//********************************************************************
// file: lin_pp515.ldf
// description: LIN decription file (LDF) for the PP515 Arrival Button
// author: James Fletcher
// date: 2019-03-26
// (c) The Invent Hive

//********************************************************************
// History
// 2019-03-26 0.01 Initial Release
// 2019-08-19 0.02 Added RGB triple for anim tint to masterCommandsFrame. Used to colour playing anim.
// Reduced byte count of buttonStatusFrame to better fit data and improve bus load.
// 2019-09-20	1.00 Ammended to new scheme supporting addressing on multiple buttons
// 2019-12-12 1.1 Converted to ARRIVAL VAN Dashboard LIN with Juoku stalk added - Chris Mather
// 2019-12-13	2.0 Imported Hella Rain Light Sensor LDF to complete dash LIN - Chris Mather
// 2020-01-07	3.0 Added LH_Stalk response error
// header

LIN_description_file;
LIN_protocol_version = "2.1";
LIN_language_version = "2.1";
LIN_speed = 19.2 kbps;

Nodes {
  Master: master, 10 ms, 0.1 ms ;
  Slaves: button1, button2, button3, button4, button5, button6, button7, button8, button9, button10, button11, button12, button13, button14, LH_Stalk, RLS_LIN ;
}

Signals {
  MASTER_Status: 8, 0, master, button1, button2 ;
  MASTER_ConfigReset: 1, 0, master, button1, button2 ;
  MASTER_ConfigEnable: 1, 0, master, button1, button2 ;
  MASTER_ConfigSetPIDOffset: 8, 0, master, button1, button2 ;
  BUTTYPE0_DefaultAnim: 8, 0, master ;
  BUTTYPE0_DefaultAnimTintR: 8, 96, master ;
  BUTTYPE0_DefaultAnimTintG: 8, 64, master ;
  BUTTYPE0_DefaultAnimTintB: 8, 64, master ;
  BUTTYPE0_TouchAnim: 8, 1, master ;
  BUTTYPE0_TouchAnimTintR: 8, 255, master ;
  BUTTYPE0_TouchAnimTintG: 8, 0, master ;
  BUTTYPE0_TouchAnimTintB: 8, 0, master ;
  BUTTYPE0_LockedAnim: 8, 0, master ;
  BUTTYPE0_LockedAnimTintR: 8, 255, master ;
  BUTTYPE0_LockedAnimTintG: 8, 0, master ;
  BUTTYPE0_LockedAnimTintB: 8, 0, master ;
  BUTTYPE1_DefaultAnim: 8, 0, master ;
  BUTTYPE1_DefaultAnimTintR: 8, 96, master ;
  BUTTYPE1_DefaultAnimTintG: 8, 64, master ;
  BUTTYPE1_DefaultAnimTintB: 8, 64, master ;
  BUTTYPE1_TouchAnim: 8, 2, master ;
  BUTTYPE1_TouchAnimTintR: 8, 0, master ;
  BUTTYPE1_TouchAnimTintG: 8, 0, master ;
  BUTTYPE1_TouchAnimTintB: 8, 255, master ;
  BUTTYPE1_LockedAnim: 8, 0, master ;
  BUTTYPE1_LockedAnimTintR: 8, 255, master ;
  BUTTYPE1_LockedAnimTintG: 8, 0, master ;
  BUTTYPE1_LockedAnimTintB: 8, 0, master ;
  BUTTON1_Type: 4, 0, master ;
  BUTTON1_LockedOut: 1, 0, master ;
  BUTTON2_Type: 4, 0, master ;
  BUTTON2_LockedOut: 1, 0, master ;
  BUTTON3_Type: 4, 0, master ;
  BUTTON3_LockedOut: 1, 0, master ;
  BUTTON4_Type: 4, 0, master ;
  BUTTON4_LockedOut: 1, 0, master ;
  BUTTON5_Type: 4, 0, master ;
  BUTTON5_LockedOut: 1, 0, master ;
  BUTTON6_Type: 4, 0, master ;
  BUTTON6_LockedOut: 1, 0, master ;
  BUTTON7_Type: 4, 0, master ;
  BUTTON7_LockedOut: 1, 0, master ;
  BUTTON8_Type: 4, 0, master ;
  BUTTON8_LockedOut: 1, 0, master ;
  BUTTON9_Type: 4, 0, master ;
  BUTTON9_LockedOut: 1, 0, master ;
  BUTTON10_Type: 4, 0, master ;
  BUTTON10_LockedOut: 1, 0, master ;
  BUTTON11_Type: 4, 0, master ;
  BUTTON11_LockedOut: 1, 0, master ;
  BUTTON12_Type: 4, 0, master ;
  BUTTON12_LockedOut: 1, 0, master ;
  BUTTON13_Type: 4, 0, master ;
  BUTTON13_LockedOut: 1, 0, master ;
  BUTTON14_Type: 4, 0, master ;
  BUTTON14_LockedOut: 1, 0, master ;
  BUTTON1_Touched: 1, 0, button1 ;
  BUTTON1_TouchTimer: 16, 0, button1 ;
  BUTTON1_Error: 1, 0, button1 ;
  BUTTON2_Touched: 1, 0, button2 ;
  BUTTON2_TouchTimer: 16, 0, button2 ;
  BUTTON2_Error: 1, 0, button2 ;
  BUTTON3_Touched: 1, 0, button3 ;
  BUTTON3_TouchTimer: 16, 0, button3 ;
  BUTTON3_Error: 1, 0, button3 ;
  BUTTON4_Touched: 1, 0, button4 ;
  BUTTON4_TouchTimer: 16, 0, button4 ;
  BUTTON4_Error: 1, 0, button4 ;
  BUTTON5_Touched: 1, 0, button5 ;
  BUTTON5_TouchTimer: 16, 0, button5 ;
  BUTTON5_Error: 1, 0, button5 ;
  BUTTON6_Touched: 1, 0, button6 ;
  BUTTON6_TouchTimer: 16, 0, button6 ;
  BUTTON6_Error: 1, 0, button6 ;
  BUTTON7_Touched: 1, 0, button7 ;
  BUTTON7_TouchTimer: 16, 0, button7 ;
  BUTTON7_Error: 1, 0, button7 ;
  BUTTON8_Touched: 1, 0, button8 ;
  BUTTON8_TouchTimer: 16, 0, button8 ;
  BUTTON8_Error: 1, 0, button8 ;
  BUTTON9_Touched: 1, 0, button9 ;
  BUTTON9_TouchTimer: 16, 0, button9 ;
  BUTTON9_Error: 1, 0, button9 ;
  BUTTON10_Touched: 1, 0, button10 ;
  BUTTON10_TouchTimer: 16, 0, button10 ;
  BUTTON10_Error: 1, 0, button10 ;
  BUTTON11_Touched: 1, 0, button11 ;
  BUTTON11_TouchTimer: 16, 0, button11 ;
  BUTTON11_Error: 1, 0, button11 ;
  BUTTON12_Touched: 1, 0, button12 ;
  BUTTON12_TouchTimer: 16, 0, button12 ;
  BUTTON12_Error: 1, 0, button12 ;
  BUTTON13_Touched: 1, 0, button13 ;
  BUTTON13_TouchTimer: 16, 0, button13 ;
  BUTTON13_Error: 1, 0, button13 ;
  BUTTON14_Touched: 1, 0, button14 ;
  BUTTON14_TouchTimer: 16, 0, button14 ;
  BUTTON14_Error: 1, 0, button14 ;
  Hi_Beam_Half_Pull: 1, 0, LH_Stalk, master ;
  Hi_Beam_Full_Pull: 1, 0, LH_Stalk, master ;
  Indicator_Half_Up: 1, 0, LH_Stalk, master ;
  Indicator_Full_Up: 1, 0, LH_Stalk, master ;
  Indicator_Half_Down: 1, 0, LH_Stalk, master ;
  Indicator_Full_Down: 1, 0, LH_Stalk, master ;
  Wiper_Half_Push: 1, 0, LH_Stalk, master ;
  Wiper_Full_Push: 1, 0, LH_Stalk, master ;
  Over_Voltage: 1, 0, LH_Stalk, master ;
  Over_Temperature: 1, 0, LH_Stalk, master ;
  LHSTALK_ERROR: 1, 0, LH_Stalk, master ;
  WIPER_SPEED: 4, 15, RLS_LIN, master ;
  STATUS_RAIN_SENS: 4, 15, RLS_LIN, master ;
  LIGHT_SWITCH_REASON: 8, 255, RLS_LIN, master ;
  RAIN_INTENSITY: 4, 15, RLS_LIN, master ;
  LIGHT_SWITCH_REQUEST: 2, 3, RLS_LIN, master ;
  STATUS_LIGHT_SENS: 2, 3, RLS_LIN, master ;
  AMBIENT_BRIGHTNESS: 8, 255, RLS_LIN, master ;
  FRONT_BRIGHTNESS: 8, 255, RLS_LIN, master ;
  ERR_STATE_CAL_RAIN_SENS: 2, 3, RLS_LIN, master ;
  ERR_STATE_RAIN_SENS: 2, 3, RLS_LIN, master ;
  ERR_STATE_CODING: 2, 3, RLS_LIN, master ;
  ERR_STATE_LIGHT_SENS: 2, 3, RLS_LIN, master ;
  ERR_STATE_OVER_TEMP: 2, 3, RLS_LIN, master ;
  ERR_STATE_OVER_VOLT: 2, 3, RLS_LIN, master ;
  SIGNAL_ERROR: 2, 3, RLS_LIN, master ;
  COMM_ERROR: 1, 0, RLS_LIN, master ;
  SCREEN_TYPE_RLS: 4, 15, RLS_LIN, master ;
  VEH_TYPE_RLS: 3, 7, RLS_LIN, master ;
  ACTIVATION_WIPE_RLS: 1, 1, RLS_LIN, master ;
  WIPER_TYPE_RLS: 2, 3, RLS_LIN, master ;
  WIPERS_OVER_SENSOR_RLS: 2, 3, RLS_LIN, master ;
  FEEDBACK_WIPE_RLS: 1, 1, RLS_LIN, master ;
  INITIALIZATION_WIPE_RLS: 1, 1, RLS_LIN, master ;
  SPEED_LIGHT_RLS: 2, 3, RLS_LIN, master ;
  LIGHT_SENSITIVITY_RLS: 4, 15, RLS_LIN, master ;
  ADDITIONAL_WIPE_TUNNEL_RLS: 1, 1, RLS_LIN, master ;
  SALT_DETECTION_RLS: 1, 1, RLS_LIN, master ;
  ICE_DETECTION_RLS: 1, 1, RLS_LIN, master ;
  RAIN_LIGHT_RLS: 1, 1, RLS_LIN, master ;
  AFTER_TUNNEL_DELAY_RLS: 8, 255, RLS_LIN, master ;
  PROD_DAY_RLS: 5, 31, RLS_LIN, master ;
  PROD_MONTH_RLS: 4, 15, RLS_LIN, master ;
  PROD_YEAR_RLS: 5, 31, RLS_LIN, master ;
  SW_MAJOR_VERSION_RLS: 4, 15, RLS_LIN, master ;
  SW_MINOR_VERSION_RLS: 4, 15, RLS_LIN, master ;
  HW_MAJOR_VERSION_RLS: 4, 15, RLS_LIN, master ;
  HW_MINOR_VERSION_RLS: 4, 15, RLS_LIN, master ;
  STATE_IGNITION: 4, 15, master, RLS_LIN ;
  WIPER_CONTROL: 8, 255, master, RLS_LIN ;
  WIPER_POSITION: 4, 15, master, RLS_LIN ;
  TEMP_EX: 16, 65535, master, RLS_LIN ;
  VEH_SPEED: 16, 65535, master, RLS_LIN ;
  RAIN_SENSITIVITY: 4, 15, master, RLS_LIN ;
  SCREEN_TYPE: 4, 15, master, RLS_LIN ;
  VEH_TYPE: 3, 7, master, RLS_LIN ;
  ACTIVATION_WIPE: 1, 1, master, RLS_LIN ;
  WIPER_TYPE: 2, 3, master, RLS_LIN ;
  WIPERS_OVER_SENSOR: 2, 3, master, RLS_LIN ;
  FEEDBACK_WIPE: 1, 1, master, RLS_LIN ;
  INITIALIZATION_WIPE: 1, 1, master, RLS_LIN ;
  SPEED_LIGHT: 2, 3, master, RLS_LIN ;
  LIGHT_SENSITIVITY: 4, 15, master, RLS_LIN ;
  ADDITIONAL_WIPE_TUNNEL: 1, 1, master, RLS_LIN ;
  SALT_DETECTION: 1, 1, master, RLS_LIN ;
  ICE_DETECTION: 1, 1, master, RLS_LIN ;
  RAIN_LIGHT: 1, 1, master, RLS_LIN ;
  AFTER_TUNNEL_DELAY: 8, 255, master, RLS_LIN ;
}

Frames {
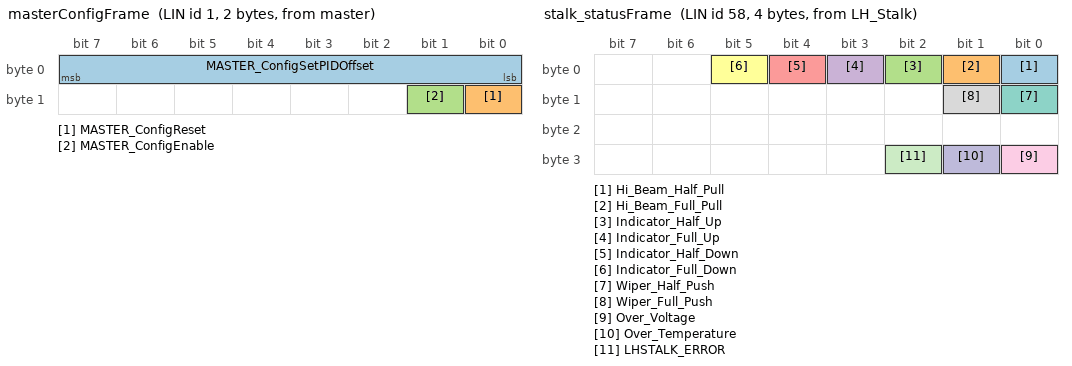
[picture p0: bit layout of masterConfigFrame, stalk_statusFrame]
  masterConfigFrame: 1, master, 2 {
    MASTER_ConfigSetPIDOffset, 0 ;
    MASTER_ConfigReset, 8 ;
    MASTER_ConfigEnable, 9 ;
  }
  masterStatusFrame: 3, master, 1 {
    MASTER_Status, 0 ;
  }
  stalk_statusFrame: 58, LH_Stalk, 4 {
    Hi_Beam_Half_Pull, 0 ;
    Hi_Beam_Full_Pull, 1 ;
    Indicator_Half_Up, 2 ;
    Indicator_Full_Up, 3 ;
    Indicator_Half_Down, 4 ;
    Indicator_Full_Down, 5 ;
    Wiper_Half_Push, 8 ;
    Wiper_Full_Push, 9 ;
    Over_Voltage, 24 ;
    Over_Temperature, 25 ;
    LHSTALK_ERROR, 26 ;
  }
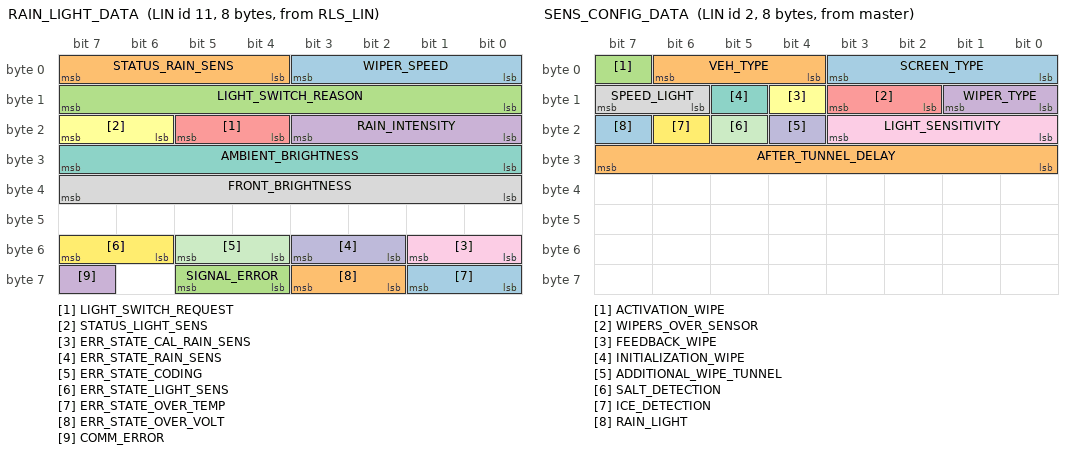
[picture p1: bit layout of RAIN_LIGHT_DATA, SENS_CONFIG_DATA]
  RAIN_LIGHT_DATA: 11, RLS_LIN, 8 {
    WIPER_SPEED, 0 ;
    STATUS_RAIN_SENS, 4 ;
    LIGHT_SWITCH_REASON, 8 ;
    RAIN_INTENSITY, 16 ;
    LIGHT_SWITCH_REQUEST, 20 ;
    STATUS_LIGHT_SENS, 22 ;
    AMBIENT_BRIGHTNESS, 24 ;
    FRONT_BRIGHTNESS, 32 ;
    ERR_STATE_CAL_RAIN_SENS, 48 ;
    ERR_STATE_RAIN_SENS, 50 ;
    ERR_STATE_CODING, 52 ;
    ERR_STATE_LIGHT_SENS, 54 ;
    ERR_STATE_OVER_TEMP, 56 ;
    ERR_STATE_OVER_VOLT, 58 ;
    SIGNAL_ERROR, 60 ;
    COMM_ERROR, 63 ;
  }
  SENS_CONFIG_DATA: 2, master, 8 {
    SCREEN_TYPE, 0 ;
    VEH_TYPE, 4 ;
    ACTIVATION_WIPE, 7 ;
    WIPER_TYPE, 8 ;
    WIPERS_OVER_SENSOR, 10 ;
    FEEDBACK_WIPE, 12 ;
    INITIALIZATION_WIPE, 13 ;
    SPEED_LIGHT, 14 ;
    LIGHT_SENSITIVITY, 16 ;
    ADDITIONAL_WIPE_TUNNEL, 20 ;
    SALT_DETECTION, 21 ;
    ICE_DETECTION, 22 ;
    RAIN_LIGHT, 23 ;
    AFTER_TUNNEL_DELAY, 24 ;
  }
  SENS_STORED_DATA: 23, RLS_LIN, 8 {
    SCREEN_TYPE_RLS, 0 ;
    VEH_TYPE_RLS, 4 ;
    ACTIVATION_WIPE_RLS, 7 ;
    WIPER_TYPE_RLS, 8 ;
    WIPERS_OVER_SENSOR_RLS, 10 ;
    FEEDBACK_WIPE_RLS, 12 ;
    INITIALIZATION_WIPE_RLS, 13 ;
    SPEED_LIGHT_RLS, 14 ;
    LIGHT_SENSITIVITY_RLS, 16 ;
    ADDITIONAL_WIPE_TUNNEL_RLS, 20 ;
    SALT_DETECTION_RLS, 21 ;
    ICE_DETECTION_RLS, 22 ;
    RAIN_LIGHT_RLS, 23 ;
    AFTER_TUNNEL_DELAY_RLS, 24 ;
    PROD_DAY_RLS, 34 ;
    PROD_MONTH_RLS, 39 ;
    PROD_YEAR_RLS, 43 ;
    SW_MAJOR_VERSION_RLS, 48 ;
    SW_MINOR_VERSION_RLS, 52 ;
    HW_MAJOR_VERSION_RLS, 56 ;
    HW_MINOR_VERSION_RLS, 60 ;
  }
}

Node_attributes {
  button1{
    LIN_protocol = "2.1" ;
    configured_NAD = 0x1 ;
    initial_NAD = 0xA ;
    product_id = 0x1234, 0x5678, 1 ;
    response_error = BUTTON1_Error ;
    P2_min = 100 ms ;
    ST_min = 20 ms ;
    N_As_timeout = 1000 ms ;
    N_Cr_timeout = 1000 ms ;
    configurable_frames {
      masterConfigFrame ;
      masterStatusFrame ;
    }
  }
  button2{
    LIN_protocol = "2.1" ;
    configured_NAD = 0x1 ;
    initial_NAD = 0xB ;
    product_id = 0x1234, 0x5678, 2 ;
    response_error = BUTTON2_Error ;
    P2_min = 100 ms ;
    ST_min = 20 ms ;
    N_As_timeout = 1000 ms ;
    N_Cr_timeout = 1000 ms ;
    configurable_frames {
      masterConfigFrame ;
      masterStatusFrame ;
    }
  }
  button3{
    LIN_protocol = "2.1" ;
    configured_NAD = 0x1 ;
    initial_NAD = 0xC ;
    product_id = 0x1234, 0x5678, 3 ;
    response_error = BUTTON3_Error ;
    P2_min = 100 ms ;
    ST_min = 20 ms ;
    N_As_timeout = 1000 ms ;
    N_Cr_timeout = 1000 ms ;
  }
  button4{
    LIN_protocol = "2.1" ;
    configured_NAD = 0x1 ;
    initial_NAD = 0xD ;
    product_id = 0x1234, 0x5678, 4 ;
    response_error = BUTTON4_Error ;
    P2_min = 100 ms ;
    ST_min = 20 ms ;
    N_As_timeout = 1000 ms ;
    N_Cr_timeout = 1000 ms ;
  }
  button5{
    LIN_protocol = "2.1" ;
    configured_NAD = 0x1 ;
    initial_NAD = 0xE ;
    product_id = 0x1234, 0x5678, 5 ;
    response_error = BUTTON5_Error ;
    P2_min = 100 ms ;
    ST_min = 20 ms ;
    N_As_timeout = 1000 ms ;
    N_Cr_timeout = 1000 ms ;
  }
  button6{
    LIN_protocol = "2.1" ;
    configured_NAD = 0x1 ;
    initial_NAD = 0xF ;
    product_id = 0x1234, 0x5678, 6 ;
    response_error = BUTTON6_Error ;
    P2_min = 100 ms ;
    ST_min = 20 ms ;
    N_As_timeout = 1000 ms ;
    N_Cr_timeout = 1000 ms ;
  }
  button7{
    LIN_protocol = "2.1" ;
    configured_NAD = 0x1 ;
    initial_NAD = 0x10 ;
    product_id = 0x1234, 0x5678, 7 ;
    response_error = BUTTON7_Error ;
    P2_min = 100 ms ;
    ST_min = 20 ms ;
    N_As_timeout = 1000 ms ;
    N_Cr_timeout = 1000 ms ;
  }
  button8{
    LIN_protocol = "2.1" ;
    configured_NAD = 0x1 ;
    initial_NAD = 0x11 ;
    product_id = 0x1234, 0x5678, 8 ;
    response_error = BUTTON8_Error ;
    P2_min = 100 ms ;
    ST_min = 20 ms ;
    N_As_timeout = 1000 ms ;
    N_Cr_timeout = 1000 ms ;
  }
  button9{
    LIN_protocol = "2.1" ;
    configured_NAD = 0x1 ;
    initial_NAD = 0x12 ;
    product_id = 0x1234, 0x5678, 9 ;
    response_error = BUTTON9_Error ;
    P2_min = 100 ms ;
    ST_min = 20 ms ;
    N_As_timeout = 1000 ms ;
    N_Cr_timeout = 1000 ms ;
  }
  button10{
    LIN_protocol = "2.1" ;
    configured_NAD = 0x1 ;
    initial_NAD = 0x13 ;
    product_id = 0x1234, 0x5678, 10 ;
    response_error = BUTTON10_Error ;
    P2_min = 100 ms ;
    ST_min = 20 ms ;
    N_As_timeout = 1000 ms ;
    N_Cr_timeout = 1000 ms ;
  }
  button11{
    LIN_protocol = "2.1" ;
    configured_NAD = 0x1 ;
    initial_NAD = 0x14 ;
    product_id = 0x1234, 0x5678, 11 ;
    response_error = BUTTON11_Error ;
    P2_min = 100 ms ;
    ST_min = 20 ms ;
    N_As_timeout = 1000 ms ;
    N_Cr_timeout = 1000 ms ;
  }
  button12{
    LIN_protocol = "2.1" ;
    configured_NAD = 0x1 ;
    initial_NAD = 0x15 ;
    product_id = 0x1234, 0x5678, 12 ;
    response_error = BUTTON12_Error ;
    P2_min = 100 ms ;
    ST_min = 20 ms ;
    N_As_timeout = 1000 ms ;
    N_Cr_timeout = 1000 ms ;
  }
  button13{
    LIN_protocol = "2.1" ;
    configured_NAD = 0x1 ;
    initial_NAD = 0x16 ;
    product_id = 0x1234, 0x5678, 13 ;
    response_error = BUTTON13_Error ;
    P2_min = 100 ms ;
    ST_min = 20 ms ;
    N_As_timeout = 1000 ms ;
    N_Cr_timeout = 1000 ms ;
  }
  button14{
    LIN_protocol = "2.1" ;
    configured_NAD = 0x1 ;
    initial_NAD = 0x1F ;
    product_id = 0x1234, 0x5678, 15 ;
    response_error = BUTTON14_Error ;
    P2_min = 100 ms ;
    ST_min = 20 ms ;
    N_As_timeout = 1000 ms ;
    N_Cr_timeout = 1000 ms ;
  }
  LH_Stalk{
    LIN_protocol = "2.1" ;
    configured_NAD = 0x2 ;
    initial_NAD = 0x3A ;
    product_id = 0x0, 0x0, 255 ;
    response_error = LHSTALK_ERROR ;
    P2_min = 50 ms ;
    ST_min = 0 ms ;
    N_As_timeout = 1000 ms ;
    N_Cr_timeout = 1000 ms ;
    configurable_frames {
      stalk_statusFrame ;
    }
  }
  RLS_LIN{
    LIN_protocol = "2.1" ;
    configured_NAD = 0x7D ;
    initial_NAD = 0x7D ;
    product_id = 0x36, 0x1200, 0 ;
    response_error = COMM_ERROR ;
    P2_min = 50 ms ;
    ST_min = 20 ms ;
    N_As_timeout = 1000 ms ;
    N_Cr_timeout = 1000 ms ;
    configurable_frames {
      RAIN_LIGHT_DATA ;
      SENS_CONFIG_DATA ;
      SENS_STORED_DATA ;
    }
  }
}

Schedule_tables {
 schTabConfig {
    masterConfigFrame delay 50 ms ;
    SENS_CONFIG_DATA delay 10 ms ;
  }
 schTabPowerUp {
    masterStatusFrame delay 20 ms ;
  }
 schTabNormal {
    masterStatusFrame delay 20 ms ;
    stalk_statusFrame delay 50 ms ;
  }
 Diagnostic {
    MasterReq delay 20 ms ;
    SlaveResp delay 20 ms ;
  }
 MasterOnly {
    MasterReq delay 20 ms ;
  }
 SlaveOnly {
    SlaveResp delay 20 ms ;
  }
}

Signal_encoding_types {
  AFTER_TUNNEL_DELAY_enc {
    physical_value, 1, 255, 1, 0 ;
    physical_value, 1, 255, 1, 0 ;
    logical_value, 0, "reserved" ;
  }
  AMBIENT_BRIGHTNESS_enc {
    physical_value, 0, 250, 100, 0 ;
    logical_value, 254, "error" ;
    logical_value, 255, "not available" ;
  }
  COMM_ERROR_enc {
    logical_value, 0, "no error" ;
    logical_value, 1, "error active" ;
  }
  ERR_STATE_enc {
    logical_value, 0, "no error" ;
    logical_value, 1, "error active" ;
    logical_value, 2, "reserved" ;
    logical_value, 3, "not available" ;
  }
  FEATURE_enc {
    logical_value, 0, "deactivated" ;
    logical_value, 1, "actived" ;
  }
  FRONT_BRIGHTNESS_enc {
    physical_value, 0, 253, 0.0067, 0 ;
    logical_value, 254, "error" ;
    logical_value, 255, "not available" ;
  }
  LIGHT_SENSITIVITY_enc {
    physical_value, 6, 14, 1, 0 ;
    physical_value, 6, 14, 1, 0 ;
    logical_value, 0, "sensitivity 0" ;
    logical_value, 1, "sensitivity 1" ;
    logical_value, 2, "sensitivity 2" ;
    logical_value, 3, "sensitivity 3" ;
    logical_value, 4, "sensitivity 4" ;
    logical_value, 5, "sensitivity 5" ;
    logical_value, 15, "not available" ;
  }
  LIGHT_SWITCH_REASON_enc {
    logical_value, 0, "Day" ;
    logical_value, 1, "Twilight" ;
    logical_value, 2, "Darkness" ;
    logical_value, 4, "Precipitation" ;
    logical_value, 8, "Tunnel" ;
    logical_value, 16, "Underground car park" ;
    logical_value, 32, "High Speed" ;
    logical_value, 255, "not available" ;
  }
  LIGHT_SWITCH_REQUEST_enc {
    logical_value, 0, "light off" ;
    logical_value, 1, "light on" ;
    logical_value, 2, "reserved" ;
    logical_value, 3, "not available" ;
  }
  RAIN_INTENSITY_enc {
    logical_value, 0, "no rain" ;
    logical_value, 1, "little rain" ;
    logical_value, 2, "normal rain" ;
    logical_value, 3, "heavy rain" ;
    logical_value, 14, "error" ;
    logical_value, 15, "not available" ;
  }
  RAIN_SENSITIVITY_enc {
    physical_value, 5, 13, 1, 0 ;
    logical_value, 0, "sensitivity 0" ;
    logical_value, 1, "sensitivity 1" ;
    logical_value, 2, "sensitivity 2" ;
    logical_value, 3, "sensitivity 3" ;
    logical_value, 4, "sensitivity 4" ;
    logical_value, 14, "error" ;
    logical_value, 15, "not available" ;
  }
  SCREEN_TYPE_enc {
    physical_value, 4, 14, 1, 0 ;
    physical_value, 4, 14, 1, 0 ;
    logical_value, 0, "Truck Sekurit R5 Green, Truck Sekurit R5 Green Heated, Truck Pilkington Tinted, Truck Pilkington Heated, Bus Pilkington 3.15LG 0.76C 3C, Bus Pilkington 4C 0.76C 3.15LG and Generic Tinted Windshield" ;
    logical_value, 1, "Bus Pilkington 4LG 0.76C 4C and Generic Tinted Thick Windshiled" ;
    logical_value, 2, "Bus Pilkington 2.5C 0.76C 2.65LG and Generic Light Tinded Windshiled" ;
    logical_value, 3, "Truck Sekurit R5 Clear, Truck Pilkington Clear, Bus Pilkington 3C 0.76C 3C and Generic Clear Windshiled" ;
    logical_value, 15, "not available" ;
  }
  SIGNAL_ERROR_enc {
    logical_value, 0, "all right" ;
    logical_value, 1, "defective" ;
    logical_value, 2, "reserved" ;
    logical_value, 3, "not available" ;
  }
  SPEED_LIGHT_enc {
    logical_value, 0, "speed light not active" ;
    logical_value, 1, "speed light active" ;
    logical_value, 2, "reserved" ;
    logical_value, 3, "not available" ;
  }
  STATE_IGNITION_enc {
    logical_value, 0, "init" ;
    logical_value, 2, "Ignition Off" ;
    logical_value, 10, "Ignition On" ;
    logical_value, 13, "Crank" ;
    logical_value, 14, "Error" ;
    logical_value, 15, "not available" ;
  }
  STATUS_LIGHT_SENS_enc {
    logical_value, 0, "no error" ;
    logical_value, 1, "error active" ;
    logical_value, 2, "reserved" ;
    logical_value, 3, "not available" ;
  }
  STATUS_RAIN_SENS_enc {
    logical_value, 0, "Normal wiping run" ;
    logical_value, 1, "Splash" ;
    logical_value, 4, "Rain sensor in fail-safe mode" ;
    logical_value, 15, "not available" ;
  }
  TEMP_EX_enc {
    physical_value, 0, 64255, 0.03125, -273 ;
    physical_value, 65024, 65279, 1, 0 ;
    physical_value, 65280, 65535, 1, 0 ;
  }
  VEH_SPEED_enc {
    physical_value, 0, 64255, 0.00390625, 0 ;
    physical_value, 65024, 65279, 1, 0 ;
    physical_value, 65280, 65535, 1, 0 ;
  }
  VEH_TYPE_enc {
    logical_value, 0, "OEM Trucks and Buses Postion 0" ;
    logical_value, 1, "Buses Position 1" ;
    logical_value, 2, "Buses Position 2" ;
    logical_value, 3, "Buses Position 3" ;
    logical_value, 4, "Buses Position 4" ;
    logical_value, 5, "reserved" ;
    logical_value, 6, "reserved" ;
    logical_value, 7, "not available" ;
  }
  WIPERS_OVER_SENSOR_enc {
    logical_value, 0, "one wiper wiping over the RLS" ;
    logical_value, 1, "two wipers wiping over the RLS" ;
    logical_value, 2, "reserved" ;
    logical_value, 3, "not available" ;
  }
  WIPER_CONTROL_enc {
    logical_value, 0, "no Action" ;
    logical_value, 1, "intermediate mode" ;
    logical_value, 2, "low speed" ;
    logical_value, 3, "high speed" ;
    logical_value, 8, "Tip wiping" ;
    logical_value, 16, "Front washing" ;
    logical_value, 254, "error" ;
    logical_value, 255, "not available" ;
  }
  WIPER_POSITION_enc {
    logical_value, 0, "in park position" ;
    logical_value, 1, "out of park position" ;
    logical_value, 14, "error" ;
    logical_value, 15, "not available" ;
  }
  WIPER_SPEED_enc {
    logical_value, 0, "wiper off" ;
    logical_value, 1, "low speed wiping" ;
    logical_value, 14, "high speed wiping" ;
    logical_value, 15, "not available" ;
  }
  WIPER_TYPE_enc {
    logical_value, 0, "2-step wiper" ;
    logical_value, 1, "multi-step wiper" ;
    logical_value, 2, "reserved" ;
    logical_value, 3, "not available" ;
  }
}

Signal_representation {
  AFTER_TUNNEL_DELAY_enc: AFTER_TUNNEL_DELAY_RLS, AFTER_TUNNEL_DELAY ;
  AMBIENT_BRIGHTNESS_enc: AMBIENT_BRIGHTNESS ;
  COMM_ERROR_enc: COMM_ERROR ;
  ERR_STATE_enc: ERR_STATE_CAL_RAIN_SENS, ERR_STATE_RAIN_SENS, ERR_STATE_CODING, ERR_STATE_LIGHT_SENS, ERR_STATE_OVER_TEMP, ERR_STATE_OVER_VOLT ;
  FEATURE_enc: ACTIVATION_WIPE_RLS, FEEDBACK_WIPE_RLS, INITIALIZATION_WIPE_RLS, ADDITIONAL_WIPE_TUNNEL_RLS, SALT_DETECTION_RLS, ICE_DETECTION_RLS, RAIN_LIGHT_RLS, ACTIVATION_WIPE, FEEDBACK_WIPE, INITIALIZATION_WIPE, ADDITIONAL_WIPE_TUNNEL, SALT_DETECTION, ICE_DETECTION, RAIN_LIGHT ;
  FRONT_BRIGHTNESS_enc: FRONT_BRIGHTNESS ;
  LIGHT_SENSITIVITY_enc: LIGHT_SENSITIVITY_RLS, LIGHT_SENSITIVITY ;
  LIGHT_SWITCH_REASON_enc: LIGHT_SWITCH_REASON ;
  LIGHT_SWITCH_REQUEST_enc: LIGHT_SWITCH_REQUEST ;
  RAIN_INTENSITY_enc: RAIN_INTENSITY ;
  RAIN_SENSITIVITY_enc: RAIN_SENSITIVITY ;
  SCREEN_TYPE_enc: SCREEN_TYPE_RLS, SCREEN_TYPE ;
  SIGNAL_ERROR_enc: SIGNAL_ERROR ;
  SPEED_LIGHT_enc: SPEED_LIGHT_RLS, SPEED_LIGHT ;
  STATE_IGNITION_enc: STATE_IGNITION ;
  STATUS_LIGHT_SENS_enc: STATUS_LIGHT_SENS ;
  STATUS_RAIN_SENS_enc: STATUS_RAIN_SENS ;
  TEMP_EX_enc: TEMP_EX ;
  VEH_SPEED_enc: VEH_SPEED ;
  VEH_TYPE_enc: VEH_TYPE_RLS, VEH_TYPE ;
  WIPERS_OVER_SENSOR_enc: WIPERS_OVER_SENSOR_RLS, WIPERS_OVER_SENSOR ;
  WIPER_CONTROL_enc: WIPER_CONTROL ;
  WIPER_POSITION_enc: WIPER_POSITION ;
  WIPER_SPEED_enc: WIPER_SPEED ;
  WIPER_TYPE_enc: WIPER_TYPE_RLS, WIPER_TYPE ;
}
